VERSION ""

NS_ :

BS_:

BU_: Kistler_S350

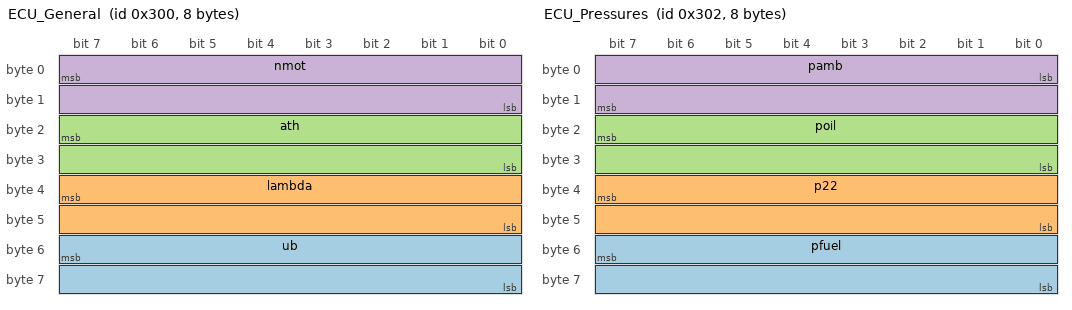
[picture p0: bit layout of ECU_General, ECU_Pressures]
BO_ 768 ECU_General: 8 MS6_Logger_CAN_Bus_1
 SG_ ub : 55|16@0- (0.01,0) [0|25.5] "V" Vector__XXX
 SG_ lambda : 39|16@0- (0.001,0) [0|5] "" Vector__XXX
 SG_ ath : 23|16@0- (0.1,0) [0|110] "%" Vector__XXX
 SG_ nmot : 7|16@0- (1,0) [0|20000] "rpm" Vector__XXX

BO_ 770 ECU_Pressures: 8 MS6_Logger_CAN_Bus_1
 SG_ pfuel : 55|16@0- (0.001,0) [0|10] "bar" Vector__XXX
 SG_ p22 : 39|16@0- (1,0) [0|5000] "mbar" Vector__XXX
 SG_ poil : 23|16@0- (0.001,0) [0|10] "bar" Vector__XXX
 SG_ pamb : 0|16@1+ (0.1,0) [0|2000] "mbar" Vector__XXX

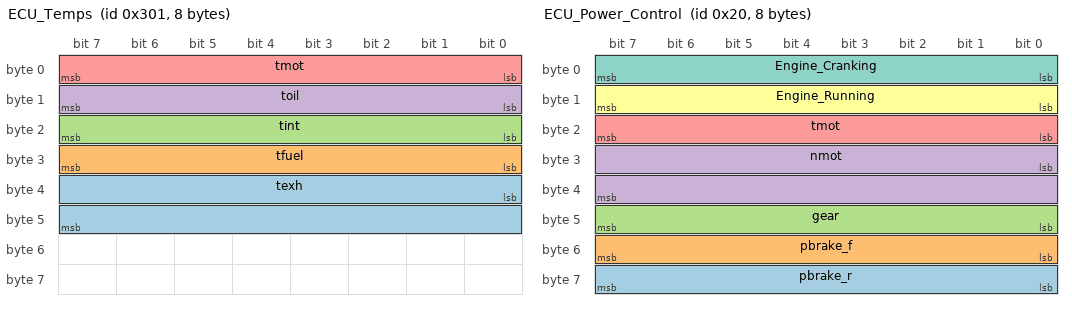
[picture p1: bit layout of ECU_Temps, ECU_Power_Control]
BO_ 769 ECU_Temps: 8 MS6_Logger_CAN_Bus_1
 SG_ texh : 32|16@1+ (1,0) [0|1250] "°C" Vector__XXX
 SG_ tfuel : 31|8@0+ (1,0) [10|80] "°C" Vector__XXX
 SG_ tint : 23|8@0+ (1,0) [10|60] "°C" Vector__XXX
 SG_ toil : 15|8@0+ (1,0) [60|150] "°C" Vector__XXX
 SG_ tmot : 0|8@1+ (1,0) [40|120] "°C" Vector__XXX

BO_ 32 ECU_Power_Control: 8 MS6_Logger_CAN_Bus_1
 SG_ pbrake_r : 56|8@1+ (1,0) [0|150] "bar" Vector__XXX
 SG_ pbrake_f : 48|8@1+ (1,0) [0|150] "bar" Vector__XXX
 SG_ gear : 40|8@1- (1,0) [-1|12] "" Vector__XXX
 SG_ nmot : 24|16@1+ (1,0) [0|20000] "rpm" Vector__XXX
 SG_ tmot : 16|8@1+ (1,0) [40|120] "°C" Vector__XXX
 SG_ Engine_Running : 8|8@1+ (1,0) [0|1] "" Vector__XXX
 SG_ Engine_Cranking : 0|8@1+ (1,0) [0|1] "" Vector__XXX

BO_ 1019 ECU_Gear_Control: 8 MS6_Logger_CAN_Bus_1
 SG_ nmot : 16|16@1- (1,0) [0|20000] "rpm" Vector__XXX
 SG_ speed : 0|16@1+ (0.01,0) [0|400] "km/h" Vector__XXX

BO_ 1568 ECU_INT_Sw_Rot_01_SDM102: 8 MS6_Logger_CAN_Bus_1
 SG_ SDM102_Tract_Ctrl : 40|8@1+ (1,0) [0|0] "" Vector__XXX
 SG_ SDM102_ECU_Map : 8|8@1+ (1,0) [0|0] "" Vector__XXX

BO_ 1576 ECU_INT_Sw_Bin_01_SDM102: 8 MS6_Logger_CAN_Bus_1
 SG_ SDM102_Launch_Ctrl_On : 3|1@1+ (1,0) [0|1] "" Vector__XXX

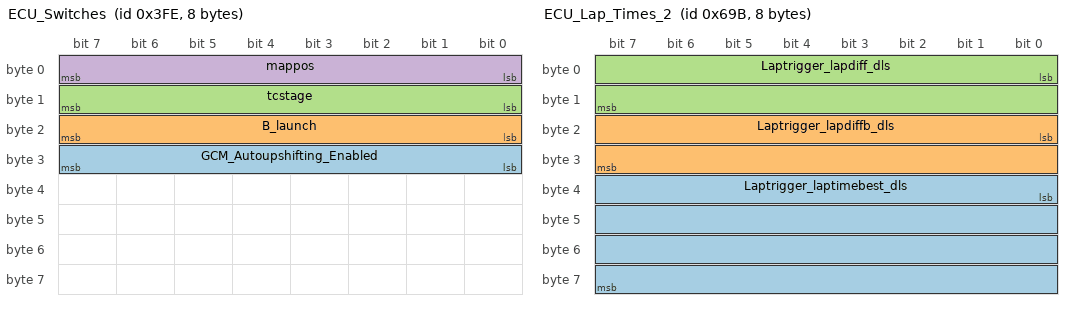
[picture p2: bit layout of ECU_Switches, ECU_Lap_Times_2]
BO_ 1022 ECU_Switches: 8 MS6_Logger_CAN_Bus_1
 SG_ GCM_Autoupshifting_Enabled : 24|8@1+ (1,0) [0|1] "" Vector__XXX
 SG_ B_launch : 16|8@1+ (1,0) [0|1] "" Vector__XXX
 SG_ tcstage : 8|8@1+ (1,0) [0|12] "" Vector__XXX
 SG_ mappos : 0|8@1+ (1,0) [0|15] "" Vector__XXX

BO_ 1690 ECU_Lap_Times: 8 MS6_Logger_CAN_Bus_1
 SG_ Laptrigger_laptime_dls : 32|32@1+ (0.01,0) [0|500] "s" Vector__XXX
 SG_ Laptrigger_laptimeold_dls : 0|32@1+ (0.01,0) [0|500] "s" Vector__XXX

BO_ 1691 ECU_Lap_Times_2: 8 MS6_Logger_CAN_Bus_1
 SG_ Laptrigger_laptimebest_dls : 32|32@1+ (0.01,0) [0|500] "s" Vector__XXX
 SG_ Laptrigger_lapdiffb_dls : 16|16@1- (0.01,0) [-20|20] "s" Vector__XXX
 SG_ Laptrigger_lapdiff_dls : 0|16@1- (0.01,0) [-20|20] "s" Vector__XXX

BO_ 1692 ECU_Lap_Times_3: 8 MS6_Logger_CAN_Bus_1
 SG_ outctr : 8|8@1+ (1,0) [0|255] "" Vector__XXX
 SG_ lapctr : 0|8@1+ (1,0) [0|255] "" Vector__XXX

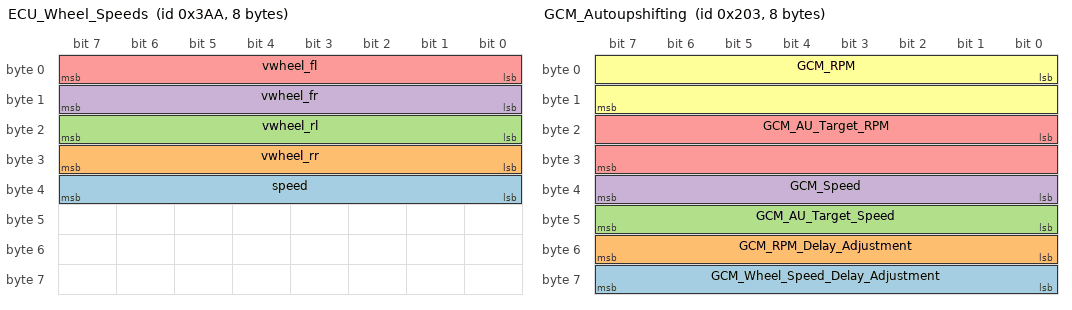
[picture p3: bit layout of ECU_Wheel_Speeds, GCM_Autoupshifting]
BO_ 938 ECU_Wheel_Speeds: 8 MS6_Logger_CAN_Bus_1
 SG_ speed : 32|8@1+ (1,0) [0|400] "km/h" Vector__XXX
 SG_ vwheel_rr : 24|8@1+ (1,0) [0|400] "km/h" Vector__XXX
 SG_ vwheel_rl : 16|8@1+ (1,0) [0|400] "km/h" Vector__XXX
 SG_ vwheel_fr : 8|8@1+ (1,0) [0|400] "km/h" Vector__XXX
 SG_ vwheel_fl : 0|8@1+ (1,0) [0|400] "km/h" Vector__XXX

BO_ 592 ECU_Autoupshifting_Targets_1: 8 MS6_Logger_CAN_Bus_1

BO_ 594 ECU_Autoupshifting_Targets_3: 8 MS6_Logger_CAN_Bus_1

BO_ 593 ECU_Autoupshifting_Targets_2: 8 MS6_Logger_CAN_Bus_1

BO_ 1020 ECU_Gear_Control_2: 8 MS6_Logger_CAN_Bus_1
 SG_ SDM102_Autoupshifting_On : 0|8@1+ (1,0) [0|1] "" Vector__XXX

BO_ 1967 IZZE_Brake_IR_Programming: 8 MS6_Logger_CAN_Bus_2

BO_ 515 GCM_Autoupshifting: 8 Vector__XXX
 SG_ GCM_Wheel_Speed_Delay_Adjustment : 56|8@1+ (0.01,0) [0|0] "" Vector__XXX
 SG_ GCM_RPM_Delay_Adjustment : 48|8@1+ (1,0) [0|0] "" Vector__XXX
 SG_ GCM_AU_Target_Speed : 40|8@1+ (1,0) [0|0] "" Vector__XXX
 SG_ GCM_Speed : 32|8@1+ (1,0) [0|0] "" Vector__XXX
 SG_ GCM_AU_Target_RPM : 16|16@1+ (1,0) [0|0] "" Vector__XXX
 SG_ GCM_RPM : 0|16@1+ (1,0) [0|0] "" Vector__XXX

BO_ 1552 GCM_MS6_Gearcut: 8 GCM
 SG_ GCM_Upshift_MS6 : 1|1@1+ (1,0) [0|0] "" Vector__XXX
 SG_ GCM_Downshift_MS6 : 0|1@1+ (1,0) [0|0] "" Vector__XXX

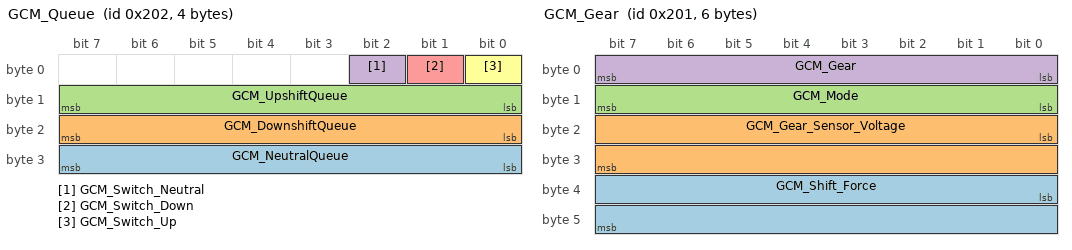
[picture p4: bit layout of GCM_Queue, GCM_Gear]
BO_ 514 GCM_Queue: 4 GCM
 SG_ GCM_NeutralQueue : 24|8@1+ (1,0) [0|0] "" Vector__XXX
 SG_ GCM_DownshiftQueue : 16|8@1+ (1,0) [0|0] "" Vector__XXX
 SG_ GCM_UpshiftQueue : 8|8@1+ (1,0) [0|0] "" Vector__XXX
 SG_ GCM_Switch_Neutral : 2|1@1+ (1,0) [0|0] "" Vector__XXX
 SG_ GCM_Switch_Down : 1|1@1+ (1,0) [0|0] "" Vector__XXX
 SG_ GCM_Switch_Up : 0|1@1+ (1,0) [0|0] "" Vector__XXX

BO_ 513 GCM_Gear: 6 GCM
 SG_ GCM_Shift_Force : 32|16@1- (0.01,0) [0|0] "N" Vector__XXX
 SG_ GCM_Gear_Sensor_Voltage : 16|16@1+ (0.0001,0) [0|0] "V" Vector__XXX
 SG_ GCM_Mode : 8|8@1+ (1,0) [0|0] "" Vector__XXX
 SG_ GCM_Gear : 0|8@1+ (1,0) [0|0] "" Vector__XXX

BO_ 15 GCM_Error: 4 GCM
 SG_ GCM_ERR_Code : 16|16@1+ (1,0) [0|0] "" Vector__XXX
 SG_ GCM_ERR_Origin_Node : 0|16@1+ (1,0) [0|0] "" Vector__XXX

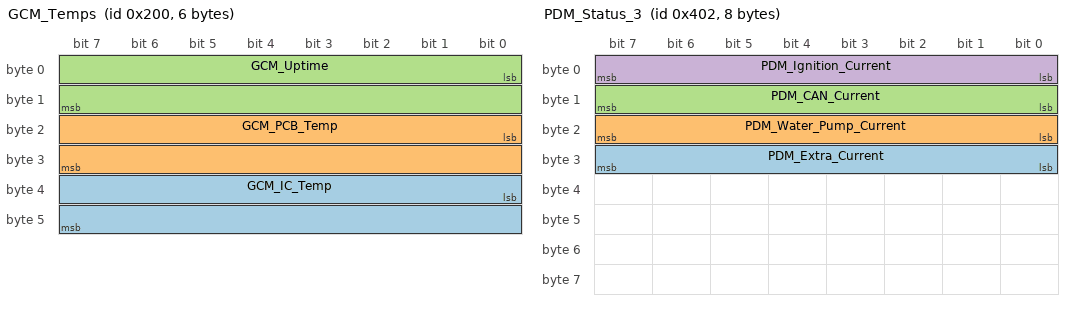
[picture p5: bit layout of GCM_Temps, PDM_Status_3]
BO_ 512 GCM_Temps: 6 GCM
 SG_ GCM_IC_Temp : 32|16@1- (0.005,0) [0|0] "C" Vector__XXX
 SG_ GCM_PCB_Temp : 16|16@1- (0.005,0) [0|0] "C" Vector__XXX
 SG_ GCM_Uptime : 0|16@1+ (1,0) [0|0] "s" Vector__XXX

BO_ 380 IMU_Z: 8 IMU
 SG_ IMU_Z_Accel : 32|16@1+ (0.0001274,-4.1746432) [0|0] "g" Vector__XXX

BO_ 376 IMU_X_Roll: 8 IMU
 SG_ IMU_X_Accel : 32|16@1+ (0.0001274,-4.1746432) [0|0] "g" Vector__XXX
 SG_ IMU_Roll_Rate : 0|16@1+ (0.005,-163.84) [0|0] "deg/s/s" Vector__XXX

BO_ 372 IMU_Y_Yaw: 8 IMU
 SG_ IMU_Y_Accel : 32|16@1+ (0.0001274,-4.1746432) [0|0] "g" Vector__XXX
 SG_ IMU_Yaw_Rate : 0|16@1+ (0.005,-163.84) [0|0] "deg/s" Vector__XXX

BO_ 1026 PDM_Status_3: 8 Vector__XXX
 SG_ PDM_Extra_Current : 24|8@1+ (1,0) [0|255] "" Vector__XXX
 SG_ PDM_Water_Pump_Current : 16|8@1+ (1,0) [0|255] "" Vector__XXX
 SG_ PDM_CAN_Current : 8|8@1+ (1,0) [0|255] "" Vector__XXX
 SG_ PDM_Ignition_Current : 0|8@1+ (1,0) [0|255] "" Vector__XXX

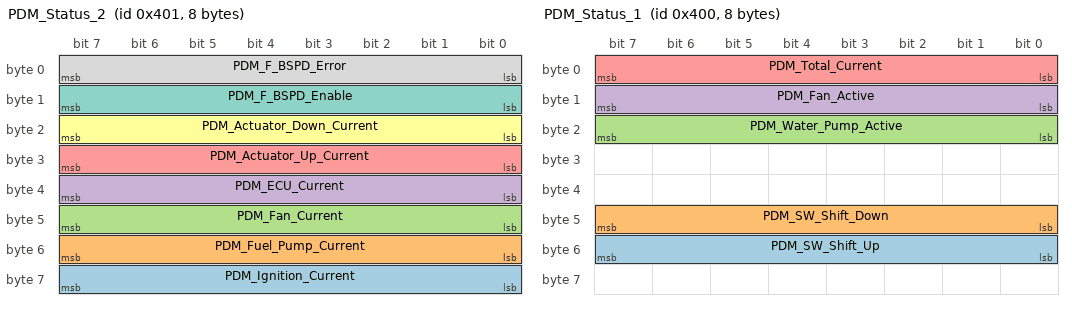
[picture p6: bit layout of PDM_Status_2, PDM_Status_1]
BO_ 1025 PDM_Status_2: 8 Vector__XXX
 SG_ PDM_Ignition_Current : 56|8@1+ (1,0) [0|255] "" Vector__XXX
 SG_ PDM_Fuel_Pump_Current : 48|8@1+ (1,0) [0|255] "" Vector__XXX
 SG_ PDM_Fan_Current : 40|8@1+ (1,0) [0|255] "" Vector__XXX
 SG_ PDM_ECU_Current : 32|8@1+ (1,0) [0|255] "" Vector__XXX
 SG_ PDM_Actuator_Up_Current : 24|8@1+ (1,0) [0|255] "" Vector__XXX
 SG_ PDM_Actuator_Down_Current : 16|8@1+ (1,0) [0|255] "" Vector__XXX
 SG_ PDM_F_BSPD_Enable : 8|8@1+ (1,0) [0|0] "" Vector__XXX
 SG_ PDM_F_BSPD_Error : 0|8@1+ (1,0) [0|0] "" Vector__XXX

BO_ 1024 PDM_Status_1: 8 PDM
 SG_ PDM_SW_Shift_Up : 48|8@1+ (1,0) [0|255] "" Vector__XXX
 SG_ PDM_SW_Shift_Down : 40|8@1+ (1,0) [0|255] "" Vector__XXX
 SG_ PDM_Water_Pump_Active : 16|8@1+ (1,0) [0|0] "" Vector__XXX
 SG_ PDM_Fan_Active : 8|8@1+ (1,0) [0|0] "" Vector__XXX
 SG_ PDM_Total_Current : 0|8@1+ (1,0) [0|255] "" Vector__XXX

BO_ 1681 SDM550_GPS_Heading: 4 PLEX
 SG_ SDM550_GPS_Heading : 7|32@0- (0.01,0) [0|0] "deg" Vector__XXX

BO_ 1680 SDM550_GPS_LatLong: 8 PLEX
 SG_ SDM550_GPS_Long : 39|32@0- (1e-07,0) [0|0] "deg" Vector__XXX
 SG_ SDM550_GPS_Lat : 7|32@0- (1e-07,0) [0|0] "deg" Vector__XXX

BO_ 5 SDM550_LapTrigger: 2 PLEX
 SG_ SDM550_Lap_Trigger : 0|16@1- (1,0) [0|0] "" Vector__XXX

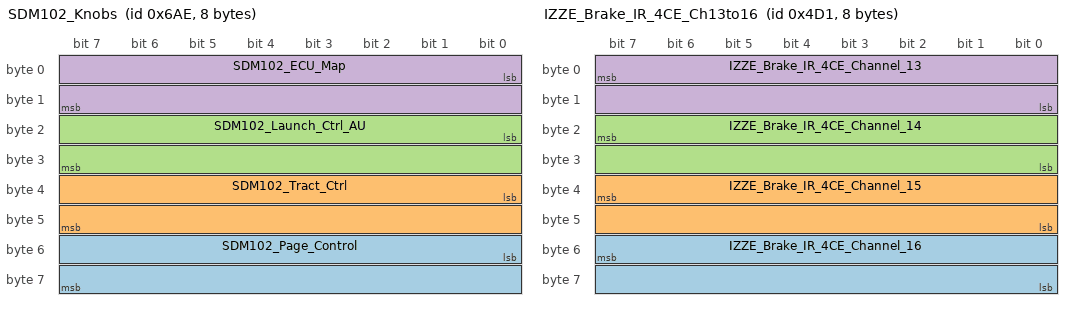
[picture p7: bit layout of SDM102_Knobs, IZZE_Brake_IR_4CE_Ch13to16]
BO_ 1710 SDM102_Knobs: 8 PLEX
 SG_ SDM102_Page_Control : 48|16@1- (1,0) [0|0] "" Vector__XXX
 SG_ SDM102_Tract_Ctrl : 32|16@1- (1,0) [0|0] "" Vector__XXX
 SG_ SDM102_Launch_Ctrl_AU : 16|16@1- (1,0) [0|0] "" Vector__XXX
 SG_ SDM102_ECU_Map : 0|16@1- (1,0) [0|0] "" Vector__XXX

BO_ 1234 IZZE_Brake_IR_4CE_Status: 8 IZZE_Brake_IR_4CE
 SG_ IZZE_Brake_IR_4CE_Internal_Temp : 7|16@0+ (0.1,-100) [0|65535] "C" Vector__XXX

BO_ 1233 IZZE_Brake_IR_4CE_Ch13to16: 8 IZZE_Brake_IR_4CE
 SG_ IZZE_Brake_IR_4CE_Channel_16 : 55|16@0+ (0.1,-100) [0|65535] "C" Vector__XXX
 SG_ IZZE_Brake_IR_4CE_Channel_15 : 39|16@0+ (0.1,-100) [0|65535] "C" Vector__XXX
 SG_ IZZE_Brake_IR_4CE_Channel_14 : 23|16@0+ (0.1,-100) [0|65535] "C" Vector__XXX
 SG_ IZZE_Brake_IR_4CE_Channel_13 : 7|16@0+ (0.1,-100) [0|65535] "C" Vector__XXX

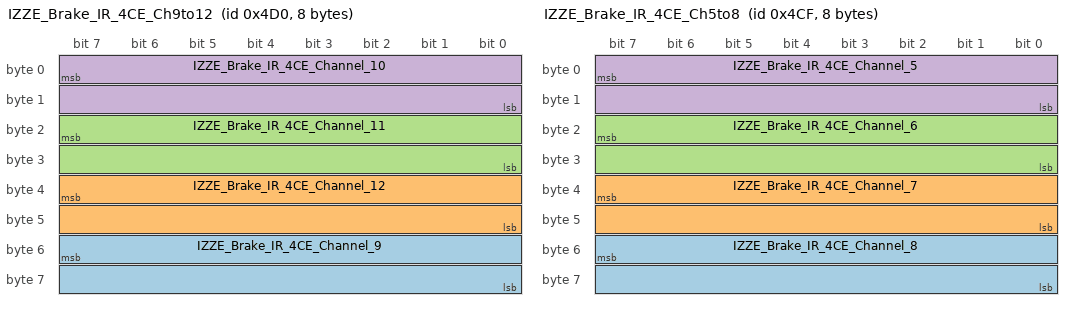
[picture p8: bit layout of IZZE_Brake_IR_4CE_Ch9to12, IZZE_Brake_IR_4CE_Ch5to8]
BO_ 1232 IZZE_Brake_IR_4CE_Ch9to12: 8 IZZE_Brake_IR_4CE
 SG_ IZZE_Brake_IR_4CE_Channel_9 : 55|16@0+ (0.1,-100) [0|65535] "C" Vector__XXX
 SG_ IZZE_Brake_IR_4CE_Channel_12 : 39|16@0+ (0.1,-100) [0|65535] "C" Vector__XXX
 SG_ IZZE_Brake_IR_4CE_Channel_11 : 23|16@0+ (0.1,-100) [0|65535] "C" Vector__XXX
 SG_ IZZE_Brake_IR_4CE_Channel_10 : 7|16@0+ (0.1,-100) [0|65535] "C" Vector__XXX

BO_ 1231 IZZE_Brake_IR_4CE_Ch5to8: 8 IZZE_Brake_IR_4CE
 SG_ IZZE_Brake_IR_4CE_Channel_8 : 55|16@0+ (0.1,-100) [0|65535] "C" Vector__XXX
 SG_ IZZE_Brake_IR_4CE_Channel_7 : 39|16@0+ (0.1,-100) [0|65535] "C" Vector__XXX
 SG_ IZZE_Brake_IR_4CE_Channel_6 : 23|16@0+ (0.1,-100) [0|65535] "C" Vector__XXX
 SG_ IZZE_Brake_IR_4CE_Channel_5 : 7|16@0+ (0.1,-100) [0|65535] "C" Vector__XXX

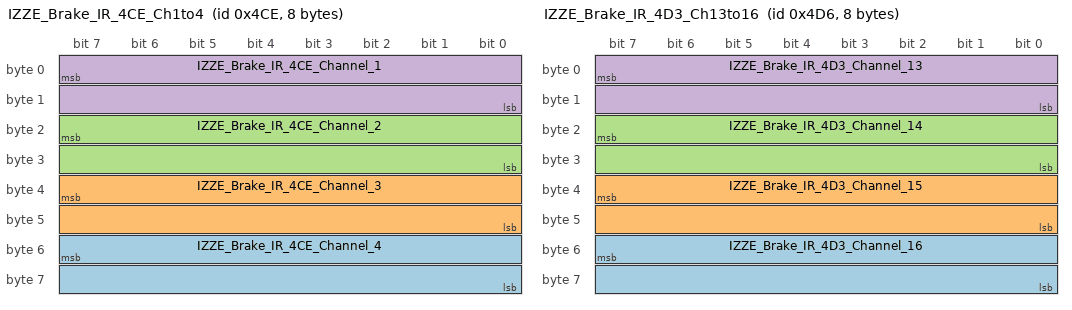
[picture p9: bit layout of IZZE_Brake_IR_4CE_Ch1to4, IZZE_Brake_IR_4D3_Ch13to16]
BO_ 1230 IZZE_Brake_IR_4CE_Ch1to4: 8 IZZE_Brake_IR_4CE
 SG_ IZZE_Brake_IR_4CE_Channel_4 : 55|16@0+ (0.1,-100) [0|65535] "C" Vector__XXX
 SG_ IZZE_Brake_IR_4CE_Channel_3 : 39|16@0+ (0.1,-100) [0|65535] "C" Vector__XXX
 SG_ IZZE_Brake_IR_4CE_Channel_2 : 23|16@0+ (0.1,-100) [0|65535] "C" Vector__XXX
 SG_ IZZE_Brake_IR_4CE_Channel_1 : 7|16@0+ (0.1,-100) [0|65535] "C" Vector__XXX

BO_ 1239 IZZE_Brake_IR_4D3_Status: 8 IZZE_Brake_IR_4D3
 SG_ IZZE_Brake_IR_4D3_Internal_Temp : 7|16@0+ (0.1,-100) [0|65535] "C" Vector__XXX

BO_ 1238 IZZE_Brake_IR_4D3_Ch13to16: 8 IZZE_Brake_IR_4D3
 SG_ IZZE_Brake_IR_4D3_Channel_16 : 55|16@0+ (0.1,-100) [0|65535] "C" Vector__XXX
 SG_ IZZE_Brake_IR_4D3_Channel_15 : 39|16@0+ (0.1,-100) [0|65535] "C" Vector__XXX
 SG_ IZZE_Brake_IR_4D3_Channel_14 : 23|16@0+ (0.1,-100) [0|65535] "C" Vector__XXX
 SG_ IZZE_Brake_IR_4D3_Channel_13 : 7|16@0+ (0.1,-100) [0|65535] "C" Vector__XXX

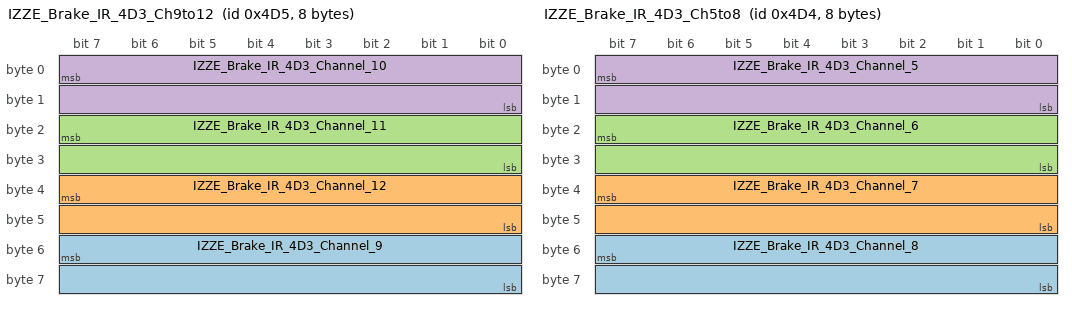
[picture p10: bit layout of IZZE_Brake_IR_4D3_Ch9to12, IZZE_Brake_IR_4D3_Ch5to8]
BO_ 1237 IZZE_Brake_IR_4D3_Ch9to12: 8 IZZE_Brake_IR_4D3
 SG_ IZZE_Brake_IR_4D3_Channel_9 : 55|16@0+ (0.1,-100) [0|65535] "C" Vector__XXX
 SG_ IZZE_Brake_IR_4D3_Channel_12 : 39|16@0+ (0.1,-100) [0|65535] "C" Vector__XXX
 SG_ IZZE_Brake_IR_4D3_Channel_11 : 23|16@0+ (0.1,-100) [0|65535] "C" Vector__XXX
 SG_ IZZE_Brake_IR_4D3_Channel_10 : 7|16@0+ (0.1,-100) [0|65535] "C" Vector__XXX

BO_ 1236 IZZE_Brake_IR_4D3_Ch5to8: 8 IZZE_Brake_IR_4D3
 SG_ IZZE_Brake_IR_4D3_Channel_8 : 55|16@0+ (0.1,-100) [0|65535] "C" Vector__XXX
 SG_ IZZE_Brake_IR_4D3_Channel_7 : 39|16@0+ (0.1,-100) [0|65535] "C" Vector__XXX
 SG_ IZZE_Brake_IR_4D3_Channel_6 : 23|16@0+ (0.1,-100) [0|65535] "C" Vector__XXX
 SG_ IZZE_Brake_IR_4D3_Channel_5 : 7|16@0+ (0.1,-100) [0|65535] "C" Vector__XXX

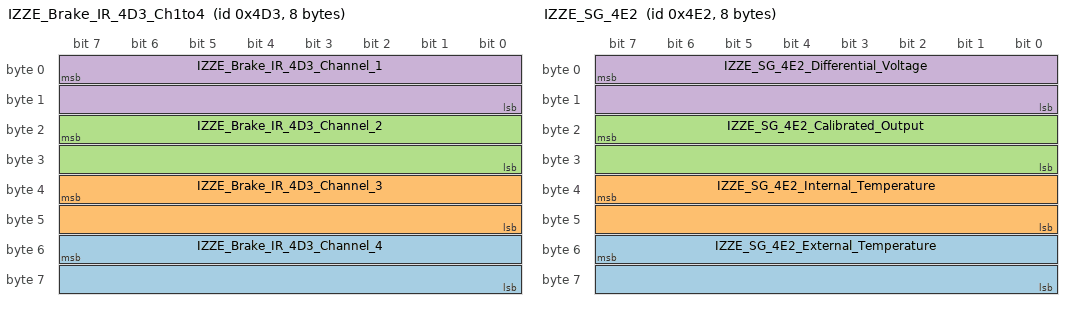
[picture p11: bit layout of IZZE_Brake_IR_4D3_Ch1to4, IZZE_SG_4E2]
BO_ 1235 IZZE_Brake_IR_4D3_Ch1to4: 8 IZZE_Brake_IR_4D3
 SG_ IZZE_Brake_IR_4D3_Channel_4 : 55|16@0+ (0.1,-100) [0|65535] "C" Vector__XXX
 SG_ IZZE_Brake_IR_4D3_Channel_3 : 39|16@0+ (0.1,-100) [0|65535] "C" Vector__XXX
 SG_ IZZE_Brake_IR_4D3_Channel_2 : 23|16@0+ (0.1,-100) [0|65535] "C" Vector__XXX
 SG_ IZZE_Brake_IR_4D3_Channel_1 : 7|16@0+ (0.1,-100) [0|65535] "C" Vector__XXX

BO_ 1250 IZZE_SG_4E2: 8 IZZE_SG_4E2
 SG_ IZZE_SG_4E2_External_Temperature : 55|16@0- (0.1,0) [0|0] "C" Vector__XXX
 SG_ IZZE_SG_4E2_Internal_Temperature : 39|16@0- (0.1,0) [0|0] "C" Vector__XXX
 SG_ IZZE_SG_4E2_Calibrated_Output : 23|16@0- (0.1,0) [0|0] "F" Vector__XXX
 SG_ IZZE_SG_4E2_Differential_Voltage : 7|16@0- (1,0) [0|0] "µV" Vector__XXX

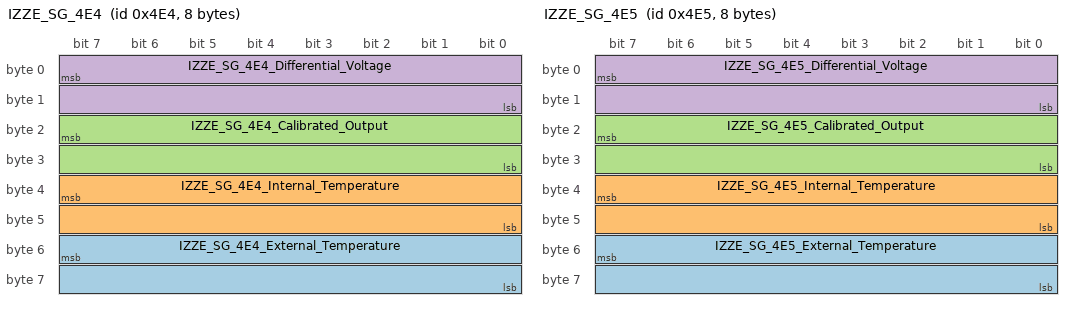
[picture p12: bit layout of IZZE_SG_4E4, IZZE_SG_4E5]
BO_ 1252 IZZE_SG_4E4: 8 IZZE_SG_4E4
 SG_ IZZE_SG_4E4_External_Temperature : 55|16@0- (0.1,0) [0|0] "C" Vector__XXX
 SG_ IZZE_SG_4E4_Internal_Temperature : 39|16@0- (0.1,0) [0|0] "C" Vector__XXX
 SG_ IZZE_SG_4E4_Calibrated_Output : 23|16@0- (0.1,0) [0|0] "F" Vector__XXX
 SG_ IZZE_SG_4E4_Differential_Voltage : 7|16@0- (1,0) [0|0] "µV" Vector__XXX

BO_ 1253 IZZE_SG_4E5: 8 IZZE_SG_4E5
 SG_ IZZE_SG_4E5_External_Temperature : 55|16@0- (0.1,0) [0|0] "C" Vector__XXX
 SG_ IZZE_SG_4E5_Internal_Temperature : 39|16@0- (0.1,0) [0|0] "C" Vector__XXX
 SG_ IZZE_SG_4E5_Calibrated_Output : 23|16@0- (0.1,0) [0|0] "F" Vector__XXX
 SG_ IZZE_SG_4E5_Differential_Voltage : 7|16@0- (1,0) [0|0] "µV" Vector__XXX

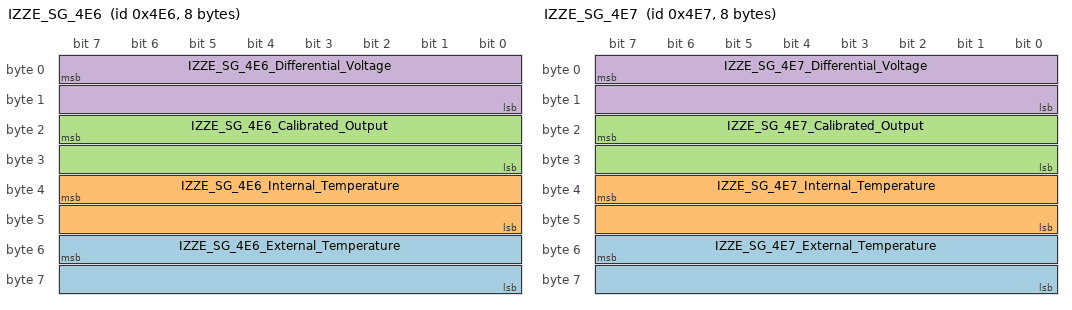
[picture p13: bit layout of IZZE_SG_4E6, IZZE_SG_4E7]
BO_ 1254 IZZE_SG_4E6: 8 IZZE_SG_4E6
 SG_ IZZE_SG_4E6_External_Temperature : 55|16@0- (0.1,0) [0|0] "C" Vector__XXX
 SG_ IZZE_SG_4E6_Internal_Temperature : 39|16@0- (0.1,0) [0|0] "C" Vector__XXX
 SG_ IZZE_SG_4E6_Calibrated_Output : 23|16@0- (0.1,0) [0|0] "F" Vector__XXX
 SG_ IZZE_SG_4E6_Differential_Voltage : 7|16@0- (1,0) [0|0] "ï¿½V" Vector__XXX

BO_ 1255 IZZE_SG_4E7: 8 IZZE_SG_4E7
 SG_ IZZE_SG_4E7_External_Temperature : 55|16@0- (0.1,0) [0|0] "C" Vector__XXX
 SG_ IZZE_SG_4E7_Internal_Temperature : 39|16@0- (0.1,0) [0|0] "C" Vector__XXX
 SG_ IZZE_SG_4E7_Calibrated_Output : 23|16@0- (0.1,0) [0|0] "F" Vector__XXX
 SG_ IZZE_SG_4E7_Differential_Voltage : 7|16@0- (1,0) [0|0] "µV" Vector__XXX

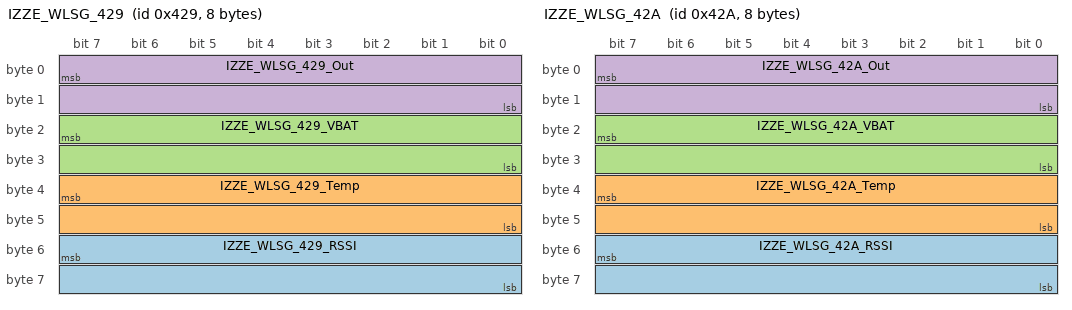
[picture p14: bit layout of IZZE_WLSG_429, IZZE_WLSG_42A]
BO_ 1065 IZZE_WLSG_429: 8 IZZE_WL_SG_429
 SG_ IZZE_WLSG_429_RSSI : 55|16@0- (1,0) [0|0] "dBm" Vector__XXX
 SG_ IZZE_WLSG_429_Temp : 39|16@0- (0.1,0) [0|0] "C" Vector__XXX
 SG_ IZZE_WLSG_429_VBAT : 23|16@0- (0.001,0) [0|0] "V" Vector__XXX
 SG_ IZZE_WLSG_429_Out : 7|16@0- (-1,0) [0|0] "uV" Vector__XXX

BO_ 1066 IZZE_WLSG_42A: 8 IZZE_WL_SG_42A
 SG_ IZZE_WLSG_42A_RSSI : 55|16@0- (1,0) [0|0] "dBm" Vector__XXX
 SG_ IZZE_WLSG_42A_Temp : 39|16@0- (0.1,0) [0|0] "C" Vector__XXX
 SG_ IZZE_WLSG_42A_VBAT : 23|16@0- (0.001,0) [0|0] "V" Vector__XXX
 SG_ IZZE_WLSG_42A_Out : 7|16@0- (1,0) [0|0] "uV" Vector__XXX

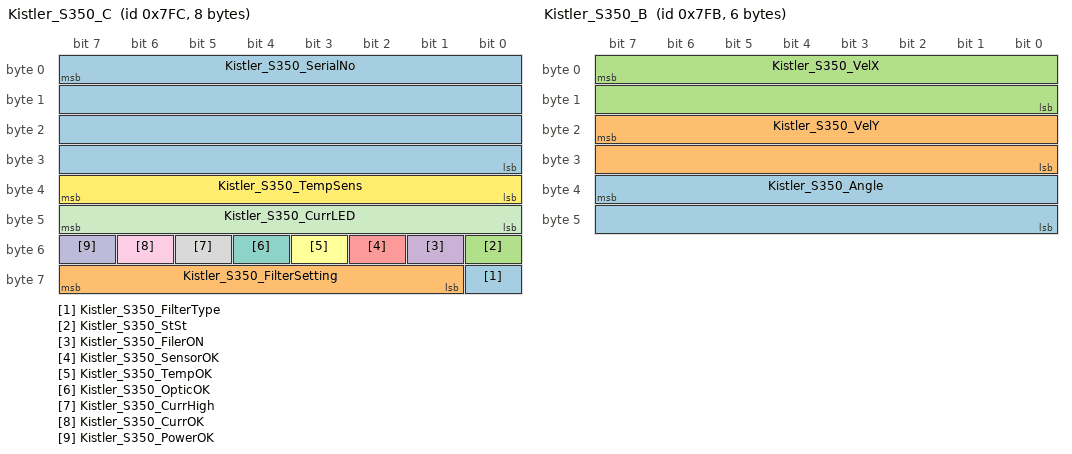
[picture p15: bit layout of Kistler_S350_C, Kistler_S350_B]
BO_ 2044 Kistler_S350_C: 8 Kistler_S350
 SG_ Kistler_S350_FilterType : 56|1@0+ (1,0) [0|1] "" Vector__XXX
 SG_ Kistler_S350_FilterSetting : 63|7@0+ (1,0) [0|127] "" Vector__XXX
 SG_ Kistler_S350_StSt : 48|1@0+ (1,0) [0|1] "" Vector__XXX
 SG_ Kistler_S350_FilerON : 49|1@0+ (1,0) [0|1] "" Vector__XXX
 SG_ Kistler_S350_SensorOK : 50|1@0+ (1,0) [0|1] "" Vector__XXX
 SG_ Kistler_S350_TempOK : 51|1@0+ (1,0) [0|1] "" Vector__XXX
 SG_ Kistler_S350_OpticOK : 52|1@0+ (1,0) [0|1] "" Vector__XXX
 SG_ Kistler_S350_CurrHigh : 53|1@0+ (1,0) [0|1] "" Vector__XXX
 SG_ Kistler_S350_CurrOK : 54|1@0+ (1,0) [0|1] "" Vector__XXX
 SG_ Kistler_S350_PowerOK : 55|1@0+ (1,0) [0|1] "" Vector__XXX
 SG_ Kistler_S350_CurrLED : 47|8@0+ (0.01,0) [0|2.55] "A" Vector__XXX
 SG_ Kistler_S350_TempSens : 39|8@0- (1,0) [-128|127] "°C" Vector__XXX
 SG_ Kistler_S350_SerialNo : 7|32@0+ (1,0) [0|4294970000] "" Vector__XXX

BO_ 2043 Kistler_S350_B: 6 Kistler_S350
 SG_ Kistler_S350_Angle : 39|16@0- (0.01,0) [-45|45] "°" Vector__XXX
 SG_ Kistler_S350_VelY : 23|16@0- (0.036,0) [-100|100] "km/h" Vector__XXX
 SG_ Kistler_S350_VelX : 7|16@0+ (0.036,0) [0|400] "km/h" Vector__XXX

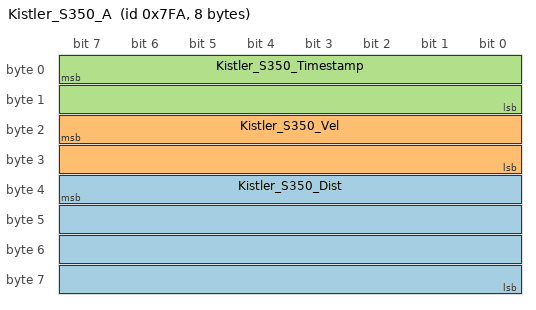
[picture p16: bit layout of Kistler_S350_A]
BO_ 2042 Kistler_S350_A: 8 Kistler_S350
 SG_ Kistler_S350_Dist : 39|32@0+ (0.001,0) [0|4294970] "m" Vector__XXX
 SG_ Kistler_S350_Vel : 23|16@0+ (0.036,0) [0|400] "km/h" Vector__XXX
 SG_ Kistler_S350_Timestamp : 7|16@0+ (1,0) [0|65535] "" Vector__XXX

CM_ BO_ 768 "RPM, Throttle Position, Lambda, Battery Voltage";
CM_ SG_ 768 ub "battery voltage";
CM_ SG_ 768 lambda "Lambda actual value";
CM_ SG_ 768 ath "throttle position";
CM_ SG_ 768 nmot "engine speed";
CM_ BO_ 770 "Ambient Pressure, Oil Pressure, Manifold Pressure, Fuel Pressure";
CM_ SG_ 770 pfuel "fuel pressure";
CM_ SG_ 770 p22 "intake manifold pressure downstream throttle";
CM_ SG_ 770 poil "oil pressure";
CM_ SG_ 770 pamb "ambient pressure";
CM_ BO_ 769 "Coolant Temp, Oil Temp, Manifold Temp, Fuel Temp, Exhaust Temp";
CM_ SG_ 769 texh "exhaust gas temperature";
CM_ SG_ 769 tfuel "fuel temperature";
CM_ SG_ 769 tint "intake air temperature";
CM_ SG_ 769 toil "oil temperature";
CM_ SG_ 769 tmot "engine temperature";
CM_ BO_ 32 "Engine_Cranking, Engine_Running, tmot, nmot, gear, pbrake_f, pbrake_r";
CM_ SG_ 32 pbrake_r "brake pressure rear";
CM_ SG_ 32 pbrake_f "brake pressure front ";
CM_ SG_ 32 gear "selected gear";
CM_ SG_ 32 nmot "engine speed";
CM_ SG_ 32 tmot "engine temperature";
CM_ SG_ 32 Engine_Running "Returns true, if (nmot > 0)";
CM_ SG_ 32 Engine_Cranking "Returns true, if (1 <= nmot <= 1000)";
CM_ BO_ 1019 "Ground Speed, RPM";
CM_ SG_ 1019 nmot "engine speed";
CM_ SG_ 1019 speed "car speed";
CM_ BO_ 1568 "Traction Control + ECU Map from SDM 102 Knobs (Internal Redirect)";
CM_ BO_ 1576 "Launch Control from SDM 102 Knob (Internal Redirect)";
CM_ SG_ 1576 SDM102_Launch_Ctrl_On "Returns true, if (SDM102_Launch_Ctrl_Only_Pre or SDM102_Launch_Ctrl_And_Autoupshifting_Pre)";
CM_ BO_ 1022 "Map Position, TC Stage, Launch Control, Auto-upshifting";
CM_ SG_ 1022 GCM_Autoupshifting_Enabled "Returns true, if (GCM_Mode == 1)";
CM_ SG_ 1022 B_launch "condition launch control active";
CM_ SG_ 1022 tcstage "traction control stage";
CM_ SG_ 1022 mappos "position of map switch";
CM_ BO_ 1690 "Previous Lap Time, Current Lap Time";
CM_ SG_ 1690 Laptrigger_laptime_dls "running lap time";
CM_ SG_ 1690 Laptrigger_laptimeold_dls "previous lap time";
CM_ BO_ 1691 "Lap Differences, Best Lap";
CM_ SG_ 1691 Laptrigger_laptimebest_dls "best lap time";
CM_ SG_ 1691 Laptrigger_lapdiffb_dls "lapdiff to best";
CM_ SG_ 1691 Laptrigger_lapdiff_dls "lapdiff to last";
CM_ BO_ 1692 "Lap Counter, Out Counter";
CM_ SG_ 1692 outctr "current outing";
CM_ SG_ 1692 lapctr "lap counter";
CM_ BO_ 938 "FL/FR/RL/RR Wheel Speeds, Ground Speed";
CM_ SG_ 938 speed "car speed";
CM_ SG_ 938 vwheel_rr "wheel speed rear right";
CM_ SG_ 938 vwheel_rl "wheel speed rear left";
CM_ SG_ 938 vwheel_fr "wheel speed front right";
CM_ SG_ 938 vwheel_fl "wheel speed front left";
CM_ BO_ 592 "Target RPMs from 1 to 4";
CM_ BO_ 594 "Target RPM + speed for 5";
CM_ BO_ 593 "Target speeds from 1 to 4";
CM_ BO_ 1020 "Auto-upshifting Enable";
CM_ SG_ 1020 SDM102_Autoupshifting_On "Returns true, if (SDM102_Launch_Ctrl_And_Autoupshifting_Pre or SDM102_Autoupshifting_Only_Pre_1 or SDM102_Autoupshifting_Only_Pre_2)";
CM_ BO_ 1967 "Programming message template for IZZE Brake IR sensor";
CM_ BO_ 515 "Paddles, Shift Queues";
CM_ BO_ 1552 "Upshift/downshift ignition cut triggers for the MS6";
CM_ BO_ 514 "Paddles, Shift Queues";
CM_ BO_ 513 "Gear, Gear Sensor Voltage, Mode, Shift force";
CM_ BO_ 15 "Error flags for IM boards";
CM_ BO_ 512 "Uptime, Temperatures";
CM_ BO_ 380 "Z accel";
CM_ BO_ 376 "Roll rate, X accel";
CM_ BO_ 372 "Yaw rate, Y accel";
CM_ BO_ 1234 "Brake IR channels 13-16";
CM_ BO_ 1233 "Brake IR channels 13-16";
CM_ BO_ 1232 "Brake IR channels 9-12";
CM_ BO_ 1231 "Brake IR channels 5-8";
CM_ BO_ 1230 "Brake IR channels 1-4";
CM_ BO_ 1239 "Brake IR channels 13-16";
CM_ BO_ 1238 "Brake IR channels 13-16";
CM_ BO_ 1237 "Brake IR channels 9-12";
CM_ BO_ 1236 "Brake IR channels 5-8";
CM_ BO_ 1235 "Brake IR channels 1-4";
CM_ BO_ 1250 "Rear left IZZE - raw voltage, calibrated output, temperatures";
CM_ BO_ 1252 "Rear right IZZE - raw voltage, calibrated output, temperatures";
CM_ BO_ 1253 "Front right IZZE - raw voltage, calibrated output, temperatures";
CM_ BO_ 1254 "Front right IZZE - raw voltage, calibrated output, temperatures";
CM_ BO_ 1255 "Front left IZZE - raw voltage, calibrated output, temperatures";
CM_ BO_ 1065 "Right wireless IZZE - Output, Battery, Temperature, RSSI";
CM_ BO_ 1066 "Left wireless IZZE - Output, Battery, Temperature, RSSI";
CM_ BO_ 2044 "Device status";
CM_ BO_ 2043 "Velocity X, Velocity Y, Slip angle";
CM_ BO_ 2042 "Timestamp, velocity, distance";
BA_DEF_  "BusType" STRING ;
BA_DEF_DEF_  "BusType" "";
BA_ "BusType" "CAN";
